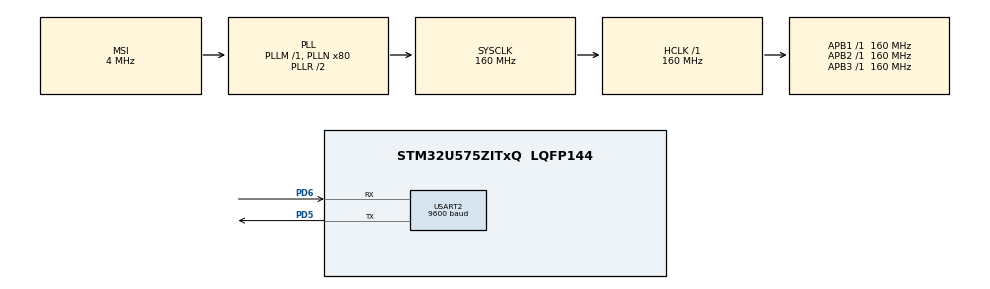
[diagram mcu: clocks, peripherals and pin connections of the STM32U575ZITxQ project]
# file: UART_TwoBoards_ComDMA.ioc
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CORTEX_M33_NS.userName=CORTEX_M33
GPDMA1.DESTINC_GPDMACH1=DMA_DINC_INCREMENTED
GPDMA1.DIRECTION_GPDMACH0=DMA_MEMORY_TO_PERIPH
GPDMA1.IPHANDLE_GPDMACH0-SIMPLEREQUEST_GPDMACH0=__NULL
GPDMA1.IPHANDLE_GPDMACH1-SIMPLEREQUEST_GPDMACH1=__NULL
GPDMA1.PRIORITY_GPDMACH0=DMA_HIGH_PRIORITY
GPDMA1.PRIORITY_GPDMACH1=DMA_HIGH_PRIORITY
GPDMA1.REQUEST_GPDMACH0=GPDMA1_REQUEST_USART2_TX
GPDMA1.REQUEST_GPDMACH1=GPDMA1_REQUEST_USART2_RX
GPDMA1.SRCINC_GPDMACH0=DMA_SINC_INCREMENTED
GPDMA1.TRANSFERALLOCATEDPORTDEST_GPDMACH0=DMA_DEST_ALLOCATED_PORT1
GPDMA1.TRANSFERALLOCATEDPORTDEST_GPDMACH1=DMA_DEST_ALLOCATED_PORT1
Mcu.Family=STM32U5
Mcu.Name=STM32U575ZITxQ
Mcu.Package=LQFP144
NVIC.GPDMA1_Channel0_IRQn=true\:0\:0\:false\:false\:true\:false\:true\:true
NVIC.GPDMA1_Channel1_IRQn=true\:0\:0\:false\:false\:true\:false\:true\:true
NVIC.PriorityGroup=NVIC_PRIORITYGROUP_4
NVIC.USART2_IRQn=true\:0\:0\:false\:false\:true\:true\:true\:true
PD5.GPIO_PuPd=GPIO_NOPULL
PD5.GPIO_Speed=GPIO_SPEED_FREQ_VERY_HIGH
PD5.Mode=Asynchronous
PD5.Signal=USART2_TX
PD6.GPIO_PuPd=GPIO_NOPULL
PD6.GPIO_Speed=GPIO_SPEED_FREQ_VERY_HIGH
PD6.Mode=Asynchronous
PD6.Signal=USART2_RX
PWR.PowerMode=PWR_SMPS_SUPPLY
ProjectManager.HeapSize=0x200
ProjectManager.StackSize=0x400
ProjectManager.TargetToolchain=EWARM V8.50
RCC.ADCFreq_Value=16000000
RCC.AHBFreq_Value=160000000
RCC.APB1Freq_Value=160000000
RCC.APB1TimFreq_Value=160000000
RCC.APB2Freq_Value=160000000
RCC.APB2TimFreq_Value=160000000
RCC.APB3Freq_Value=160000000
RCC.CortexFreq_Value=160000000
RCC.DACCLockSelectionVirtual=RCC_DAC1CLKSOURCE_LSI
RCC.DACCLockSelectionVirtualString=RCC_DAC1CLKSOURCE_LSI
RCC.EPOD_VALUE=4000000
RCC.HCLKFreq_Value=160000000
RCC.HSE_VALUE=16000000
RCC.HSI48_VALUE=48000000
RCC.HSI_VALUE=16000000
RCC.LSE_VALUE=32768
RCC.LSIDIV_VALUE=32000
RCC.MSI_VALUE=4000000
RCC.PLLN=80
RCC.SYSCLKFreq_VALUE=160000000
RCC.SYSCLKSource=RCC_SYSCLKSOURCE_PLLCLK
RCC.USBFreq_Value=48000000
RCC.VCOOutputFreq_Value=320000000
USART2.BaudRate=9600
USART2.VirtualMode-Asynchronous=VM_ASYNC
VP_GPDMA1_VS_GPDMACH0.Mode=SIMPLEREQUEST_GPDMACH0
VP_GPDMA1_VS_GPDMACH1.Mode=SIMPLEREQUEST_GPDMACH1
VP_ICACHE_VS_ICACHE.Mode=DirectMappedCache
VP_LPBAMQUEUE_VS_QUEUE.Mode=QUEUEMODE
VP_LPBAM_VS_SIG1.Mode=SmartRun
VP_LPBAM_VS_SIG4.Mode=LPDMA1
VP_PWR_VS_DBSignals.Mode=DisableDeadBatterySignals
VP_PWR_VS_LPOM.Mode=PowerOptimisation
VP_PWR_VS_SECSignals.Mode=Security/Privilege
board=custom

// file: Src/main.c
/* USER CODE BEGIN Header */
/**
  ******************************************************************************
  * @file           : main.c
  * @brief          : Main program body
  ******************************************************************************
  * @attention
  *
  * Copyright (c) 2021 STMicroelectronics.
  * All rights reserved.
  *
  * This software is licensed under terms that can be found in the LICENSE file
  * in the root directory of this software component.
  * If no LICENSE file comes with this software, it is provided AS-IS.
  *
  ******************************************************************************
  */
/* USER CODE END Header */
#include "main.h"

/* USER CODE BEGIN PD */
#define TRANSMITTER_BOARD
/* USER CODE END PD */

UART_HandleTypeDef huart2;
DMA_HandleTypeDef handle_GPDMA1_Channel1;
DMA_HandleTypeDef handle_GPDMA1_Channel0;

/* USER CODE BEGIN PV */
__IO ITStatus UartReady = RESET;
__IO uint32_t UserButtonStatus = 0;  /* set to 1 after User Button interrupt  */

/* Buffer used for transmission :
   Size should be a Multiple of cache line size (32 bytes) */
ALIGN_32BYTES (uint8_t aTxBuffer[]) = " *****UART_TwoBoards communication based on DMA*****  *****UART_TwoBoards communication based on DMA*****   *****UART_TwoBoards communication based on DMA***** ";

/* Buffer used for reception :
   Size should be a Multiple of cache line size (32 bytes) */
ALIGN_32BYTES (uint8_t aRxBuffer[RXBUFFERSIZE]);
/* USER CODE END PV */

void SystemClock_Config(void);
static void SystemPower_Config(void);
static void MX_GPIO_Init(void);
static void MX_GPDMA1_Init(void);
static void MX_ICACHE_Init(void);
static void MX_USART2_UART_Init(void);
/* USER CODE BEGIN PFP */
static uint16_t Buffercmp(uint8_t* pBuffer1, uint8_t* pBuffer2, uint16_t BufferLength);
/* USER CODE END PFP */

int main(void)
{

  /* USER CODE BEGIN 1 */
  /* STM32U5xx HAL library initialization:
       - Configure the Flash prefetch
       - Configure the Systick to generate an interrupt each 1 msec
       - Set NVIC Group Priority to 3
       - Low Level Initialization
     */
  /* USER CODE END 1 */

  /* MCU Configuration--------------------------------------------------------*/

  /* Reset of all peripherals, Initializes the Flash interface and the Systick. */
  HAL_Init();

  /* Configure the System Power */
  SystemPower_Config();

  /* Configure the system clock */
  SystemClock_Config();

  /* USER CODE BEGIN SysInit */
  /* Configure LED1, LED2 and LED3 */
  BSP_LED_Init(LED1);
  BSP_LED_Init(LED2);
  BSP_LED_Init(LED3);
  /* USER CODE END SysInit */

  /* Initialize all configured peripherals */
  MX_GPIO_Init();
  MX_GPDMA1_Init();
  MX_ICACHE_Init();
  MX_USART2_UART_Init();
  /* USER CODE BEGIN 2 */
#ifdef TRANSMITTER_BOARD

  /* Configure User push-button in Interrupt mode */
  BSP_PB_Init(BUTTON_USER, BUTTON_MODE_EXTI);

  /* Wait for User push-button press before starting the Communication.
     In the meantime, LED2 is blinking */
  while(UserButtonStatus == 0)
  {
      /* Toggle LED2*/
      BSP_LED_Toggle(LED2);
      HAL_Delay(100);
  }

  BSP_LED_Off(LED2);

  /* The board sends the message and expects to receive it back */

  /*##-2- Start the transmission process #####################################*/
  /* While the UART in reception process, user can transmit data through
     "aTxBuffer" buffer */
  if(HAL_UART_Transmit_DMA(&huart2, (uint8_t*)aTxBuffer, TXBUFFERSIZE)!= HAL_OK)
  {
    Error_Handler();
  }

  /*##-3- Wait for the end of the transfer ###################################*/
  while (UartReady != SET)
  {
  }

  /* Reset transmission flag */
  UartReady = RESET;

  /*##-4- Put UART peripheral in reception process ###########################*/
  if(HAL_UART_Receive_DMA(&huart2, (uint8_t *)aRxBuffer, RXBUFFERSIZE) != HAL_OK)
  {
    Error_Handler();
  }

#else

  /* The board receives the message and sends it back */

  /*##-2- Put UART peripheral in reception process ###########################*/
  if(HAL_UART_Receive_DMA(&huart2, (uint8_t *)aRxBuffer, RXBUFFERSIZE) != HAL_OK)
  {
    Error_Handler();
  }

  /*##-3- Wait for the end of the transfer ###################################*/
  /* While waiting for message to come from the other board, LED2 is
     blinking according to the following pattern: a double flash every half-second */
  while (UartReady != SET)
  {
      BSP_LED_On(LED2);
      HAL_Delay(100);
      BSP_LED_Off(LED2);
      HAL_Delay(100);
      BSP_LED_On(LED2);
      HAL_Delay(100);
      BSP_LED_Off(LED2);
      HAL_Delay(500);
  }

  /* Reset transmission flag */
  UartReady = RESET;
  BSP_LED_Off(LED2);

  /*##-4- Start the transmission process #####################################*/
  if(HAL_UART_Transmit_DMA(&huart2, (uint8_t*)aTxBuffer, TXBUFFERSIZE)!= HAL_OK)
  {
    Error_Handler();
  }

#endif /* TRANSMITTER_BOARD */

  /*##-5- Wait for the end of the transfer ###################################*/
  while (UartReady != SET)
  {
  }

  /* Reset transmission flag */
  UartReady = RESET;

  /*##-6- Compare the sent and received buffers ##############################*/
  if(Buffercmp((uint8_t*)aTxBuffer,(uint8_t*)aRxBuffer,RXBUFFERSIZE))
  {
    Error_Handler();
  }

  /* Turn on LED1 if test passes then enter infinite loop */
  BSP_LED_On(LED1);

  /* USER CODE END 2 */

  /* Infinite loop */
  while (1)
  {

  }
}

void SystemClock_Config(void)
{
  RCC_OscInitTypeDef RCC_OscInitStruct = {0};
  RCC_ClkInitTypeDef RCC_ClkInitStruct = {0};

  /** Configure the main internal regulator output voltage
  */
  if (HAL_PWREx_ControlVoltageScaling(PWR_REGULATOR_VOLTAGE_SCALE1) != HAL_OK)
  {
    Error_Handler();
  }

  /** Initializes the CPU, AHB and APB buses clocks
  */
  RCC_OscInitStruct.OscillatorType = RCC_OSCILLATORTYPE_MSI;
  RCC_OscInitStruct.MSIState = RCC_MSI_ON;
  RCC_OscInitStruct.MSICalibrationValue = RCC_MSICALIBRATION_DEFAULT;
  RCC_OscInitStruct.MSIClockRange = RCC_MSIRANGE_4;
  RCC_OscInitStruct.PLL.PLLState = RCC_PLL_ON;
  RCC_OscInitStruct.PLL.PLLSource = RCC_PLLSOURCE_MSI;
  RCC_OscInitStruct.PLL.PLLMBOOST = RCC_PLLMBOOST_DIV1;
  RCC_OscInitStruct.PLL.PLLM = 1;
  RCC_OscInitStruct.PLL.PLLN = 80;
  RCC_OscInitStruct.PLL.PLLP = 2;
  RCC_OscInitStruct.PLL.PLLQ = 2;
  RCC_OscInitStruct.PLL.PLLR = 2;
  RCC_OscInitStruct.PLL.PLLRGE = RCC_PLLVCIRANGE_0;
  RCC_OscInitStruct.PLL.PLLFRACN = 0;
  if (HAL_RCC_OscConfig(&RCC_OscInitStruct) != HAL_OK)
  {
    Error_Handler();
  }

  /** Initializes the CPU, AHB and APB buses clocks
  */
  RCC_ClkInitStruct.ClockType = RCC_CLOCKTYPE_HCLK|RCC_CLOCKTYPE_SYSCLK
                              |RCC_CLOCKTYPE_PCLK1|RCC_CLOCKTYPE_PCLK2
                              |RCC_CLOCKTYPE_PCLK3;
  RCC_ClkInitStruct.SYSCLKSource = RCC_SYSCLKSOURCE_PLLCLK;
  RCC_ClkInitStruct.AHBCLKDivider = RCC_SYSCLK_DIV1;
  RCC_ClkInitStruct.APB1CLKDivider = RCC_HCLK_DIV1;
  RCC_ClkInitStruct.APB2CLKDivider = RCC_HCLK_DIV1;
  RCC_ClkInitStruct.APB3CLKDivider = RCC_HCLK_DIV1;

  if (HAL_RCC_ClockConfig(&RCC_ClkInitStruct, FLASH_LATENCY_4) != HAL_OK)
  {
    Error_Handler();
  }
}

/**
  * @brief Power Configuration
  * @retval None
  */
static void SystemPower_Config(void)
{

  /*
   * Disable the internal Pull-Up in Dead Battery pins of UCPD peripheral
   */
  HAL_PWREx_DisableUCPDDeadBattery();

  /*
   * Switch to SMPS regulator instead of LDO
   */
  if (HAL_PWREx_ConfigSupply(PWR_SMPS_SUPPLY) != HAL_OK)
  {
    Error_Handler();
  }
}

static void MX_GPDMA1_Init(void)
{

  /* Peripheral clock enable */
  __HAL_RCC_GPDMA1_CLK_ENABLE();

  /* GPDMA1 interrupt Init */
    HAL_NVIC_SetPriority(GPDMA1_Channel0_IRQn, 0, 0);
    HAL_NVIC_EnableIRQ(GPDMA1_Channel0_IRQn);
    HAL_NVIC_SetPriority(GPDMA1_Channel1_IRQn, 0, 0);
    HAL_NVIC_EnableIRQ(GPDMA1_Channel1_IRQn);

}

static void MX_ICACHE_Init(void)
{

  /** Enable instruction cache in 1-way (direct mapped cache)
  */
  if (HAL_ICACHE_ConfigAssociativityMode(ICACHE_1WAY) != HAL_OK)
  {
    Error_Handler();
  }
  if (HAL_ICACHE_Enable() != HAL_OK)
  {
    Error_Handler();
  }

}

static void MX_USART2_UART_Init(void)
{

  huart2.Instance = USART2;
  huart2.Init.BaudRate = 9600;
  huart2.Init.WordLength = UART_WORDLENGTH_8B;
  huart2.Init.StopBits = UART_STOPBITS_1;
  huart2.Init.Parity = UART_PARITY_NONE;
  huart2.Init.Mode = UART_MODE_TX_RX;
  huart2.Init.HwFlowCtl = UART_HWCONTROL_NONE;
  huart2.Init.OverSampling = UART_OVERSAMPLING_16;
  huart2.Init.OneBitSampling = UART_ONE_BIT_SAMPLE_DISABLE;
  huart2.Init.ClockPrescaler = UART_PRESCALER_DIV1;
  huart2.AdvancedInit.AdvFeatureInit = UART_ADVFEATURE_NO_INIT;
  if (HAL_UART_Init(&huart2) != HAL_OK)
  {
    Error_Handler();
  }
  if (HAL_UARTEx_SetTxFifoThreshold(&huart2, UART_TXFIFO_THRESHOLD_1_8) != HAL_OK)
  {
    Error_Handler();
  }
  if (HAL_UARTEx_SetRxFifoThreshold(&huart2, UART_RXFIFO_THRESHOLD_1_8) != HAL_OK)
  {
    Error_Handler();
  }
  if (HAL_UARTEx_DisableFifoMode(&huart2) != HAL_OK)
  {
    Error_Handler();
  }

}

static void MX_GPIO_Init(void)
{

  /* GPIO Ports Clock Enable */
  __HAL_RCC_GPIOD_CLK_ENABLE();

}

/* USER CODE BEGIN 4 */
/**
  * @brief  Tx Transfer completed callback
  * @param  UartHandle: UART handle.
  * @note   This example shows a simple way to report end of DMA Tx transfer, and
  *         you can add your own implementation.
  * @retval None
  */
void HAL_UART_TxCpltCallback(UART_HandleTypeDef *UartHandle)
{
  /* Set transmission flag: transfer complete */
  UartReady = SET;

#ifdef TRANSMITTER_BOARD
  /* Turn LED1 on: Transfer in transmission process is correct */
  BSP_LED_On(LED1);
#else
	/* Turn LED1 off: Transfer in transmission process is correct */
  BSP_LED_Off(LED1);
#endif  /* TRANSMITTER_BOARD */

}

/**
  * @brief  Rx Transfer completed callback
  * @param  UartHandle: UART handle
  * @note   This example shows a simple way to report end of DMA Rx transfer, and
  *         you can add your own implementation.
  * @retval None
  */
void HAL_UART_RxCpltCallback(UART_HandleTypeDef *UartHandle)
{
  /* Set transmission flag: transfer complete */
  UartReady = SET;

#ifdef TRANSMITTER_BOARD
  /* Turn LED1 off: Transfer in reception process is correct */
  BSP_LED_Off(LED1);
#else
  /* Turn LED1 on: Transfer in reception process is correct */
  BSP_LED_On(LED1);
#endif  /* TRANSMITTER_BOARD */

}

/**
  * @brief  UART error callbacks
  * @param  UartHandle: UART handle
  * @note   This example shows a simple way to report transfer error, and you can
  *         add your own implementation.
  * @retval None
  */
void HAL_UART_ErrorCallback(UART_HandleTypeDef *UartHandle)
{
    Error_Handler();
}

/**
  * @brief EXTI line detection callbacks
  * @param GPIO_Pin: Specifies the pins connected EXTI line
  * @retval None
  */
void BSP_PB_Callback(Button_TypeDef Button)
{
  if(Button == BUTTON_USER)
  {
    UserButtonStatus = 1;
  }
}

/**
  * @brief  Compares two buffers.
  * @param  pBuffer1, pBuffer2: buffers to be compared.
  * @param  BufferLength: buffer's length
  * @retval 0  : pBuffer1 identical to pBuffer2
  *         >0 : pBuffer1 differs from pBuffer2
  */
static uint16_t Buffercmp(uint8_t* pBuffer1, uint8_t* pBuffer2, uint16_t BufferLength)
{
  while (BufferLength--)
  {
    if ((*pBuffer1) != *pBuffer2)
    {
      return BufferLength;
    }
    pBuffer1++;
    pBuffer2++;
  }

  return 0;
}
/* USER CODE END 4 */

void Error_Handler(void)
{
  /* USER CODE BEGIN Error_Handler_Debug */
  /* Turn LED3 on */
  BSP_LED_On(LED3);
  __disable_irq();
  while (1)
  {
  }
  /* USER CODE END Error_Handler_Debug */
}
